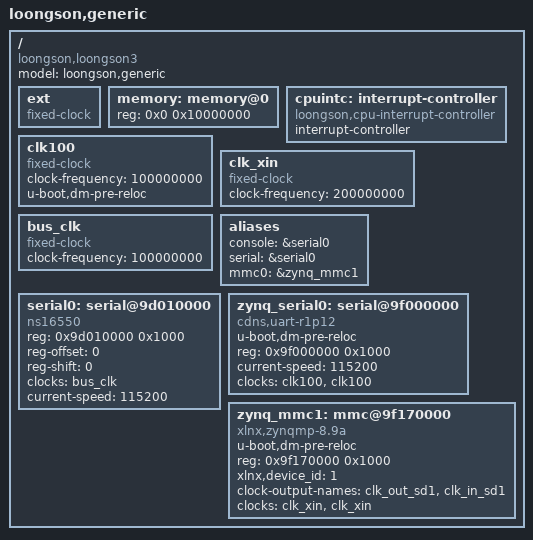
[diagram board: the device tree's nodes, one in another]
/dts-v1/;

/ {
    model = "loongson,generic";
    compatible = "loongson,loongson3";
    #address-cells = <1>;
    #size-cells = <1>;

	ext: ext {
		compatible = "fixed-clock";
		#clock-cells = <0>;
	};
	
	memory: memory@0 {
		device_type = "memory";
		reg = <0x0 0x10000000>;
	};

	cpuintc: interrupt-controller {
	compatible = "loongson,cpu-interrupt-controller";
        interrupt-controller;
		#interrupt-cells = <1>;
	};

	clk100: clk100 {
		compatible = "fixed-clock";
		#clock-cells = <0>;
		clock-frequency = <100000000>;
		u-boot,dm-pre-reloc;
	};
	clk_xin: clk_xin {
		compatible = "fixed-clock";
		#clock-cells = <0>;
		clock-frequency = <200000000>;
	};
	bus_clk: bus_clk {
		compatible = "fixed-clock";
        clock-frequency = <100000000>;
		#clock-cells = <0>;
	};

	aliases {
		// console = &zynq_serial0;
        // serial = &zynq_serial0;
		console = &serial0;
        serial = &serial0;
        mmc0 = &zynq_mmc1;
	};
	
	serial0: serial@9d010000 {
		compatible = "ns16550";
		reg = <0x9d010000 0x1000>;
        reg-offset = <0>;
        reg-shift = <0>;
        clocks = <&bus_clk>;
        current-speed = <115200>;
	};

	zynq_serial0: serial@9f000000 {
    	u-boot,dm-pre-reloc;
    	compatible = "cdns,uart-r1p12", "xlnx,xuartps";
		status = "okay";
    	reg = <0x9f000000 0x1000>;
    	clock-names = "uart_clk", "pclk";
        current-speed = <115200>;
		clocks = <&clk100 &clk100>;
	};

	zynq_mmc1: mmc@9f170000 {
		u-boot,dm-pre-reloc;
		compatible = "xlnx,zynqmp-8.9a", "arasan,sdhci-8.9a";
		status = "okay";
		reg = <0x9f170000 0x1000>;
		clock-names = "clk_xin", "clk_ahb";
		xlnx,device_id = <1>;
		#stream-id-cells = <1>;
		#clock-cells = <1>;
		clock-output-names = "clk_out_sd1", "clk_in_sd1";
		clocks = <&clk_xin &clk_xin>;
	};
};

